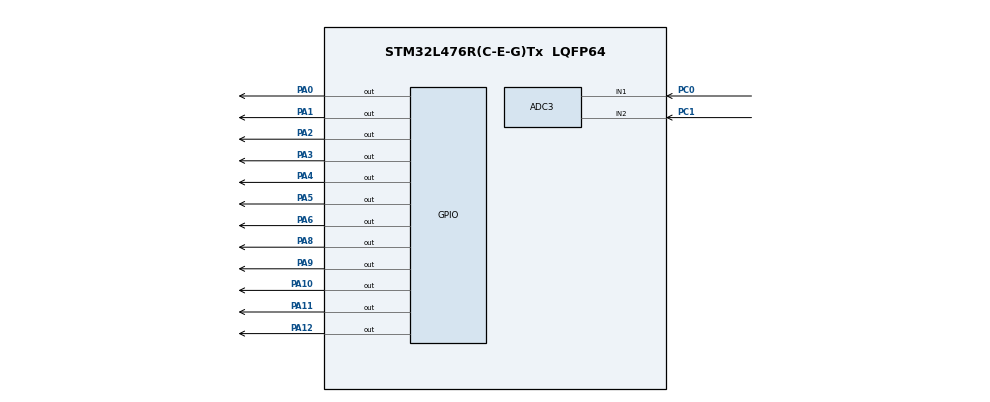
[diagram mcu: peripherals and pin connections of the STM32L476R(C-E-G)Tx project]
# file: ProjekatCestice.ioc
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ADC1.Channel-5\#ChannelRegularConversion=ADC_CHANNEL_1
ADC1.NbrOfConversionFlag=1
ADC1.OffsetNumber-5\#ChannelRegularConversion=ADC_OFFSET_NONE
ADC1.Rank-5\#ChannelRegularConversion=1
ADC1.SamplingTime-5\#ChannelRegularConversion=ADC_SAMPLETIME_2CYCLES_5
ADC1.SingleDiff-5\#ChannelRegularConversion=ADC_DIFFERENTIAL_ENDED
ADC1.master=1
ADC2.Channel-2\#ChannelRegularConversion=ADC_CHANNEL_1
ADC2.NbrOfConversionFlag=1
ADC2.OffsetNumber-2\#ChannelRegularConversion=ADC_OFFSET_NONE
ADC2.Rank-2\#ChannelRegularConversion=1
ADC2.SamplingTime-2\#ChannelRegularConversion=ADC_SAMPLETIME_2CYCLES_5
ADC2.SingleDiff-2\#ChannelRegularConversion=ADC_DIFFERENTIAL_ENDED
ADC3.Channel-1\#ChannelRegularConversion=ADC_CHANNEL_1
ADC3.ContinuousConvMode=ENABLE
ADC3.NbrOfConversionFlag=1
ADC3.OffsetNumber-1\#ChannelRegularConversion=ADC_OFFSET_NONE
ADC3.Rank-1\#ChannelRegularConversion=1
ADC3.SamplingTime-1\#ChannelRegularConversion=ADC_SAMPLETIME_2CYCLES_5
ADC3.SingleDiff-1\#ChannelRegularConversion=ADC_DIFFERENTIAL_ENDED
Mcu.Family=STM32L4
Mcu.Name=STM32L476R(C-E-G)Tx
Mcu.Package=LQFP64
NVIC.PriorityGroup=NVIC_PRIORITYGROUP_4
PA0.Signal=GPIO_Output
PA1.Signal=GPIO_Output
PA10.Signal=GPIO_Output
PA11.Signal=GPIO_Output
PA12.Signal=GPIO_Output
PA13\ (JTMS-SWDIO).Mode=Serial_Wire
PA13\ (JTMS-SWDIO).Signal=SYS_JTMS-SWDIO
PA14\ (JTCK-SWCLK).Mode=Serial_Wire
PA14\ (JTCK-SWCLK).Signal=SYS_JTCK-SWCLK
PA2.Signal=GPIO_Output
PA3.Signal=GPIO_Output
PA4.Signal=GPIO_Output
PA5.Signal=GPIO_Output
PA6.Signal=GPIO_Output
PA8.Signal=GPIO_Output
PA9.Signal=GPIO_Output
PC0.Signal=ADCx_IN1
PC1.Signal=ADCx_IN2
PC2.Signal=ADCx_IN3
ProjectManager.HeapSize=0x200
ProjectManager.StackSize=0x400
ProjectManager.TargetToolchain=STM32CubeIDE
RCC.HSE_VALUE=8000000
RCC.HSI_VALUE=16000000
RCC.LSE_VALUE=32768
RCC.MSI_VALUE=4000000
RCC.VCOOutputFreq_Value=32000000
SH.ADCx_IN1.0=ADC3_IN1,IN1-Differential
SH.ADCx_IN1.1=ADC1_IN1,IN1-Differential
SH.ADCx_IN1.2=ADC2_IN1,IN1-Differential
SH.ADCx_IN2.0=ADC3_IN2,IN1-Differential
SH.ADCx_IN2.1=ADC1_IN2,IN1-Differential
SH.ADCx_IN2.2=ADC2_IN2,IN1-Differential
SH.ADCx_IN3.0=ADC3_IN3
board=custom

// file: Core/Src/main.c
/* USER CODE BEGIN Header */
/**
  ******************************************************************************
  * @file           : main.c
  * @brief          : Main program body
  ******************************************************************************
  * @attention
  *
  * Copyright (c) 2023 STMicroelectronics.
  * All rights reserved.
  *
  * This software is licensed under terms that can be found in the LICENSE file
  * in the root directory of this software component.
  * If no LICENSE file comes with this software, it is provided AS-IS.
  *
  ******************************************************************************
  */
/* USER CODE END Header */
#include "main.h"
#include "LoRaMac.h"

#define DEVICE_EUI "0011223344556677"  // Replace with your Device EUI
#define APP_EUI "AABBCCDDEEFF0011"     // Replace with your Application EUI
#define APP_KEY "112233445566778899AABBCCDDEEFF00" // Replace with your App Key
#define enableLcd GPIO_PIN_15

/* USER CODE BEGIN Includes */

#include <stdio.h>

/* Private includes ----------------------------------------------------------*/
/* USER CODE BEGIN Includes */

/* USER CODE END Includes */

ADC_HandleTypeDef hadc1;
ADC_HandleTypeDef hadc2;
ADC_HandleTypeDef hadc3;

float pm1, pm2_5, pm10;
char buffer[512];

uint16_t res;
int duzina_poruke;

void SystemClock_Config(void);
static void MX_GPIO_Init(void);

void LCD_Init(){
	LCD_fun(0x38,0);
	LCD_fun(0x0C,0);
	LCD_fun(0x06,0);
	LCD_fun(0x01,0);
	LCD_fun(0x80,0);
}

void LCD_fun(uint8_t value, uint8_t ind){

		uint8_t data1;

		HAL_GPIO_WritePin(GPIOA, GPIO_PIN_14, ind);

		data1 = value & 0x01;
		HAL_GPIO_WritePin(GPIOA, GPIO_PIN_6, data1);

		data1 = (value >> 1) & 0x01;
		HAL_GPIO_WritePin(GPIOA, GPIO_PIN_7, data1);

		data1 = (value >> 2) & 0x01;
		HAL_GPIO_WritePin(GPIOA, GPIO_PIN_8, data1);

		data1 = (value >> 3) & 0x01;
		HAL_GPIO_WritePin(GPIOA, GPIO_PIN_9, data1);

		data1 = (value >> 4) & 0x01;
		HAL_GPIO_WritePin(GPIOA, GPIO_PIN_10, data1);

		data1 = (value >> 5) & 0x01;
		HAL_GPIO_WritePin(GPIOA, GPIO_PIN_11, data1);

		data1 = (value >> 6) & 0x01;
		HAL_GPIO_WritePin(GPIOA, GPIO_PIN_12, data1);

		data1 = (value >> 7) & 0x01;
		HAL_GPIO_WritePin(GPIOA, GPIO_PIN_13, data1);

		HAL_GPIO_WritePin(GPIOA, enableLcd, GPIO_PIN_SET);
		HAL_Delay(5);
		HAL_GPIO_WritePin(GPIOA, enableLcd, GPIO_PIN_RESET);
}

/* USER CODE END 0 */
void ispis_LCD(char tekst[]){

	int i=0;
	LCD_fun(0x01, 0);

	while(tekst[i]){
		LCD_fun(tekst[i],1);
		i++;
	}
}

float pm_sensor_read_pm1()
{
	HAL_ADC_Start(&hadc1);
	HAL_ADC_PollForConversion(&hadc1, HAL_MAX_DELAY);
	res=HAL_ADC_GetValue(&hadc1);

	pm1=res*100/4095;

	HAL_Delay(1000);
	duzina_poruke = sprintf(buffer, "%u", pm1);
	//Slanje podataka
	return pm1;
}

float pm_sensor_read_pm25()
{
	HAL_ADC_Start(&hadc2);
	HAL_ADC_PollForConversion(&hadc2, HAL_MAX_DELAY);
	res=HAL_ADC_GetValue(&hadc2);

	pm2_5=res*100/4095;

	HAL_Delay(1000);
	duzina_poruke = sprintf(buffer, "%u", pm2_5);
	//Slanje podataka
	return pm2_5;
}

float pm_sensor_read_pm10()
{
	HAL_ADC_Start(&hadc3);
	HAL_ADC_PollForConversion(&hadc3, HAL_MAX_DELAY);
	res=HAL_ADC_GetValue(&hadc3);

	pm10=res*100/4095;

	HAL_Delay(1000);
	duzina_poruke = sprintf(buffer, "%u", pm10);
	//Slanje podataka
	return pm10;
}

/*
void setup() {
    // Initialize HAL, peripherals, and system clock
    HAL_Init();
    SystemClock_Config();

    // Initialize PM sensor
    pm_sensor_init();

    // Initialize LoRaWAN communication
    lorawan_init();

    // Configure LoRaWAN parameters
    lorawan_set_device_eui(DEVICE_EUI);
    lorawan_set_app_eui(APP_EUI);
    lorawan_set_app_key(APP_KEY);
}
*/

void loop() {
    // Read PM sensor values
    float pm1_value = pm_sensor_read_pm1();
    float pm25_value = pm_sensor_read_pm25();
    float pm10_value = pm_sensor_read_pm10();

    // Convert PM values to payload format (JSON)
    char payload[150];
    sprintf(payload, sizeof(payload), "{\"PM1\":%.2f,\"PM2.5\":%.2f,\"PM10\":%.2f}", pm1_value, pm25_value, pm10_value);

    // Join LoRaWAN network if not joined already
    //if (!IsReJoin0Required()) {
    //	IsReJoin0Required();
    //}

    // Send payload if joined
    //if (lorawan_is_joined()) {
    //    lorawan_send_payload(payload);
    //}

    ispis_LCD(payload);

    // Sleep or wait for next cycle
    HAL_Delay(10000); // 10 seconds delay
}
/* USER CODE END PV */

void SystemClock_Config(void);
void PeriphCommonClock_Config(void);
static void MX_GPIO_Init(void);
static void MX_ADC1_Init(void);
static void MX_ADC2_Init(void);
static void MX_ADC3_Init(void);

int main(void)
{

  /* MCU Configuration--------------------------------------------------------*/

  /* Reset of all peripherals, Initializes the Flash interface and the Systick. */
  HAL_Init();

  /* Configure the system clock */
  SystemClock_Config();

/* Configure the peripherals common clocks */
  PeriphCommonClock_Config();

  /* Initialize all configured peripherals */
  MX_GPIO_Init();
  MX_ADC1_Init();
  MX_ADC2_Init();
  MX_ADC3_Init();

  /* Infinite loop */
  while (1)
  {
	  loop();
  }
}

void SystemClock_Config(void)
{
  RCC_OscInitTypeDef RCC_OscInitStruct = {0};
  RCC_ClkInitTypeDef RCC_ClkInitStruct = {0};

  /** Configure the main internal regulator output voltage
  */
  if (HAL_PWREx_ControlVoltageScaling(PWR_REGULATOR_VOLTAGE_SCALE1) != HAL_OK)
  {
    Error_Handler();
  }

  /** Initializes the RCC Oscillators according to the specified parameters
  * in the RCC_OscInitTypeDef structure.
  */
  RCC_OscInitStruct.OscillatorType = RCC_OSCILLATORTYPE_MSI;
  RCC_OscInitStruct.MSIState = RCC_MSI_ON;
  RCC_OscInitStruct.MSICalibrationValue = 0;
  RCC_OscInitStruct.MSIClockRange = RCC_MSIRANGE_6;
  RCC_OscInitStruct.PLL.PLLState = RCC_PLL_NONE;
  if (HAL_RCC_OscConfig(&RCC_OscInitStruct) != HAL_OK)
  {
    Error_Handler();
  }

  /** Initializes the CPU, AHB and APB buses clocks
  */
  RCC_ClkInitStruct.ClockType = RCC_CLOCKTYPE_HCLK|RCC_CLOCKTYPE_SYSCLK
                              |RCC_CLOCKTYPE_PCLK1|RCC_CLOCKTYPE_PCLK2;
  RCC_ClkInitStruct.SYSCLKSource = RCC_SYSCLKSOURCE_MSI;
  RCC_ClkInitStruct.AHBCLKDivider = RCC_SYSCLK_DIV1;
  RCC_ClkInitStruct.APB1CLKDivider = RCC_HCLK_DIV1;
  RCC_ClkInitStruct.APB2CLKDivider = RCC_HCLK_DIV1;

  if (HAL_RCC_ClockConfig(&RCC_ClkInitStruct, FLASH_LATENCY_0) != HAL_OK)
  {
    Error_Handler();
  }
}

void PeriphCommonClock_Config(void)
{
  RCC_PeriphCLKInitTypeDef PeriphClkInit = {0};

  /** Initializes the peripherals clock
  */
  PeriphClkInit.PeriphClockSelection = RCC_PERIPHCLK_ADC;
  PeriphClkInit.AdcClockSelection = RCC_ADCCLKSOURCE_PLLSAI1;
  PeriphClkInit.PLLSAI1.PLLSAI1Source = RCC_PLLSOURCE_MSI;
  PeriphClkInit.PLLSAI1.PLLSAI1M = 1;
  PeriphClkInit.PLLSAI1.PLLSAI1N = 8;
  PeriphClkInit.PLLSAI1.PLLSAI1P = RCC_PLLP_DIV7;
  PeriphClkInit.PLLSAI1.PLLSAI1Q = RCC_PLLQ_DIV2;
  PeriphClkInit.PLLSAI1.PLLSAI1R = RCC_PLLR_DIV2;
  PeriphClkInit.PLLSAI1.PLLSAI1ClockOut = RCC_PLLSAI1_ADC1CLK;
  if (HAL_RCCEx_PeriphCLKConfig(&PeriphClkInit) != HAL_OK)
  {
    Error_Handler();
  }
}

static void MX_ADC1_Init(void)
{

  ADC_MultiModeTypeDef multimode = {0};
  ADC_ChannelConfTypeDef sConfig = {0};

  /** Common config
  */
  hadc1.Instance = ADC1;
  hadc1.Init.ClockPrescaler = ADC_CLOCK_ASYNC_DIV1;
  hadc1.Init.Resolution = ADC_RESOLUTION_12B;
  hadc1.Init.DataAlign = ADC_DATAALIGN_RIGHT;
  hadc1.Init.ScanConvMode = ADC_SCAN_DISABLE;
  hadc1.Init.EOCSelection = ADC_EOC_SINGLE_CONV;
  hadc1.Init.LowPowerAutoWait = DISABLE;
  hadc1.Init.ContinuousConvMode = DISABLE;
  hadc1.Init.NbrOfConversion = 1;
  hadc1.Init.DiscontinuousConvMode = DISABLE;
  hadc1.Init.ExternalTrigConv = ADC_SOFTWARE_START;
  hadc1.Init.ExternalTrigConvEdge = ADC_EXTERNALTRIGCONVEDGE_NONE;
  hadc1.Init.DMAContinuousRequests = DISABLE;
  hadc1.Init.Overrun = ADC_OVR_DATA_PRESERVED;
  hadc1.Init.OversamplingMode = DISABLE;
  if (HAL_ADC_Init(&hadc1) != HAL_OK)
  {
    Error_Handler();
  }

  /** Configure the ADC multi-mode
  */
  multimode.Mode = ADC_MODE_INDEPENDENT;
  if (HAL_ADCEx_MultiModeConfigChannel(&hadc1, &multimode) != HAL_OK)
  {
    Error_Handler();
  }

  /** Configure Regular Channel
  */
  sConfig.Channel = ADC_CHANNEL_1;
  sConfig.Rank = ADC_REGULAR_RANK_1;
  sConfig.SamplingTime = ADC_SAMPLETIME_2CYCLES_5;
  sConfig.SingleDiff = ADC_DIFFERENTIAL_ENDED;
  sConfig.OffsetNumber = ADC_OFFSET_NONE;
  sConfig.Offset = 0;
  if (HAL_ADC_ConfigChannel(&hadc1, &sConfig) != HAL_OK)
  {
    Error_Handler();
  }

}

static void MX_ADC2_Init(void)
{

  ADC_ChannelConfTypeDef sConfig = {0};

  /** Common config
  */
  hadc2.Instance = ADC2;
  hadc2.Init.ClockPrescaler = ADC_CLOCK_ASYNC_DIV1;
  hadc2.Init.Resolution = ADC_RESOLUTION_12B;
  hadc2.Init.DataAlign = ADC_DATAALIGN_RIGHT;
  hadc2.Init.ScanConvMode = ADC_SCAN_DISABLE;
  hadc2.Init.EOCSelection = ADC_EOC_SINGLE_CONV;
  hadc2.Init.LowPowerAutoWait = DISABLE;
  hadc2.Init.ContinuousConvMode = DISABLE;
  hadc2.Init.NbrOfConversion = 1;
  hadc2.Init.DiscontinuousConvMode = DISABLE;
  hadc2.Init.ExternalTrigConv = ADC_SOFTWARE_START;
  hadc2.Init.ExternalTrigConvEdge = ADC_EXTERNALTRIGCONVEDGE_NONE;
  hadc2.Init.DMAContinuousRequests = DISABLE;
  hadc2.Init.Overrun = ADC_OVR_DATA_PRESERVED;
  hadc2.Init.OversamplingMode = DISABLE;
  if (HAL_ADC_Init(&hadc2) != HAL_OK)
  {
    Error_Handler();
  }

  /** Configure Regular Channel
  */
  sConfig.Channel = ADC_CHANNEL_1;
  sConfig.Rank = ADC_REGULAR_RANK_1;
  sConfig.SamplingTime = ADC_SAMPLETIME_2CYCLES_5;
  sConfig.SingleDiff = ADC_DIFFERENTIAL_ENDED;
  sConfig.OffsetNumber = ADC_OFFSET_NONE;
  sConfig.Offset = 0;
  if (HAL_ADC_ConfigChannel(&hadc2, &sConfig) != HAL_OK)
  {
    Error_Handler();
  }

}

static void MX_ADC3_Init(void)
{

  ADC_ChannelConfTypeDef sConfig = {0};

  /** Common config
  */
  hadc3.Instance = ADC3;
  hadc3.Init.ClockPrescaler = ADC_CLOCK_ASYNC_DIV1;
  hadc3.Init.Resolution = ADC_RESOLUTION_12B;
  hadc3.Init.DataAlign = ADC_DATAALIGN_RIGHT;
  hadc3.Init.ScanConvMode = ADC_SCAN_DISABLE;
  hadc3.Init.EOCSelection = ADC_EOC_SINGLE_CONV;
  hadc3.Init.LowPowerAutoWait = DISABLE;
  hadc3.Init.ContinuousConvMode = ENABLE;
  hadc3.Init.NbrOfConversion = 1;
  hadc3.Init.DiscontinuousConvMode = DISABLE;
  hadc3.Init.ExternalTrigConv = ADC_SOFTWARE_START;
  hadc3.Init.ExternalTrigConvEdge = ADC_EXTERNALTRIGCONVEDGE_NONE;
  hadc3.Init.DMAContinuousRequests = DISABLE;
  hadc3.Init.Overrun = ADC_OVR_DATA_PRESERVED;
  hadc3.Init.OversamplingMode = DISABLE;
  if (HAL_ADC_Init(&hadc3) != HAL_OK)
  {
    Error_Handler();
  }

  /** Configure Regular Channel
  */
  sConfig.Channel = ADC_CHANNEL_1;
  sConfig.Rank = ADC_REGULAR_RANK_1;
  sConfig.SamplingTime = ADC_SAMPLETIME_2CYCLES_5;
  sConfig.SingleDiff = ADC_DIFFERENTIAL_ENDED;
  sConfig.OffsetNumber = ADC_OFFSET_NONE;
  sConfig.Offset = 0;
  if (HAL_ADC_ConfigChannel(&hadc3, &sConfig) != HAL_OK)
  {
    Error_Handler();
  }

}

static void MX_GPIO_Init(void)
{
  GPIO_InitTypeDef GPIO_InitStruct = {0};

  /* GPIO Ports Clock Enable */
  __HAL_RCC_GPIOC_CLK_ENABLE();
  __HAL_RCC_GPIOA_CLK_ENABLE();

  /*Configure GPIO pin Output Level */
  HAL_GPIO_WritePin(GPIOA, GPIO_PIN_0|GPIO_PIN_1|GPIO_PIN_2|GPIO_PIN_3
                          |GPIO_PIN_4|GPIO_PIN_5|GPIO_PIN_6|GPIO_PIN_8
                          |GPIO_PIN_9|GPIO_PIN_10|GPIO_PIN_11|GPIO_PIN_12, GPIO_PIN_RESET);

  /*Configure GPIO pins : PA0 PA1 PA2 PA3
                           PA4 PA5 PA6 PA8
                           PA9 PA10 PA11 PA12 */
  GPIO_InitStruct.Pin = GPIO_PIN_0|GPIO_PIN_1|GPIO_PIN_2|GPIO_PIN_3
                          |GPIO_PIN_4|GPIO_PIN_5|GPIO_PIN_6|GPIO_PIN_8
                          |GPIO_PIN_9|GPIO_PIN_10|GPIO_PIN_11|GPIO_PIN_12;
  GPIO_InitStruct.Mode = GPIO_MODE_OUTPUT_PP;
  GPIO_InitStruct.Pull = GPIO_NOPULL;
  GPIO_InitStruct.Speed = GPIO_SPEED_FREQ_LOW;
  HAL_GPIO_Init(GPIOA, &GPIO_InitStruct);

}

void Error_Handler(void)
{
  __disable_irq();
  while (1)
  {
  }
}
